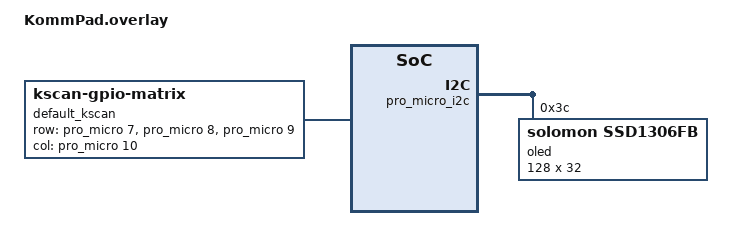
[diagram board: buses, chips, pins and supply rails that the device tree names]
#include <dt-bindings/zmk/matrix_transform.h>
#include <physical_layouts.dtsi>

/ {
    chosen {
        zmk,kscan = &default_kscan;
        zmk,physical-layout = &default_physical_layout;
        zmk,studio-unlock-on-start;
        zephyr,display = &oled;
    };

    default_kscan: kscan {
        compatible = "zmk,kscan-gpio-matrix";
        label = "default_kscan";
        diode-direction = "col2row";

        row-gpios = <&pro_micro 7 (GPIO_ACTIVE_HIGH | GPIO_PULL_DOWN)>,
                    <&pro_micro 8 (GPIO_ACTIVE_HIGH | GPIO_PULL_DOWN)>,
                    <&pro_micro 9 (GPIO_ACTIVE_HIGH | GPIO_PULL_DOWN)>;
                    
        col-gpios = <&pro_micro 10 GPIO_ACTIVE_HIGH>;
    };

    default_transform: matrix_transform {
        compatible = "zmk,matrix-transform";
        rows = <3>;
        columns = <1>;

        map = <
            RC(0,0)
            RC(1,0)
            RC(2,0)
        >;
    };

    default_physical_layout: physical_layout_0 {
        compatible = "zmk,physical-layout";
        display-name = "Default";
        transform = <&default_transform>;
        kscan = <&default_kscan>;

        keys  //                     w   h    x    y     rot    rx    ry
            = <&key_physical_attrs 100 100    0    0       0     0     0>
            , <&key_physical_attrs 100 100    0  100       0     0     0>
            , <&key_physical_attrs 100 100    0  200       0     0     0>
            ;
    };

};

&pro_micro_i2c {
    status = "okay";

    oled: ssd1306@3c {
        compatible = "solomon,ssd1306fb";
        reg = <0x3c>;
        width = <128>;
        height = <32>;
        segment-offset = <0>;
        page-offset = <0>;
        display-offset = <0>;
        multiplex-ratio = <31>;
        segment-remap;
        com-invdir;
        prechargep = <0x22>;
    };
};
